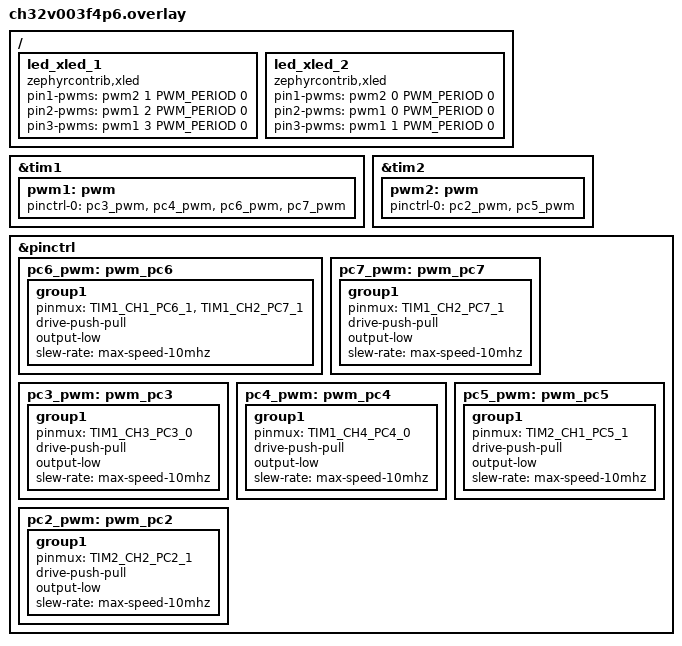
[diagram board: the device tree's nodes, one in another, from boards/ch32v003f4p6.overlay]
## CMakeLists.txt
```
cmake_minimum_required(VERSION 3.20.0)
list(APPEND ZEPHYR_EXTRA_MODULES ${CMAKE_CURRENT_LIST_DIR}/../..)
find_package(Zephyr REQUIRED HINTS $ENV{ZEPHYR_BASE})
project(xled_dual_sample)

target_sources(app PRIVATE src/main.c)
```

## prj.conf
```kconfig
CONFIG_PWM=y
CONFIG_GPIO=y
CONFIG_XLED=y

CONFIG_PRINTK=y
CONFIG_SERIAL=y
CONFIG_CONSOLE=y
CONFIG_UART_CONSOLE=y

CONFIG_CBPRINTF_NANO=y
CONFIG_CBPRINTF_REDUCED_INTEGRAL=y
CONFIG_TIMEOUT_64BIT=n

CONFIG_MINIMAL_LIBC=y
CONFIG_SYSTEM_WORKQUEUE_STACK_SIZE=160
CONFIG_MAIN_STACK_SIZE=320
CONFIG_IDLE_STACK_SIZE=64
CONFIG_ISR_STACK_SIZE=128

CONFIG_UART_INTERRUPT_DRIVEN=n
CONFIG_BOOT_BANNER=n
CONFIG_ASSERT=n
CONFIG_ERRNO=n
CONFIG_THREAD_NAME=n
```

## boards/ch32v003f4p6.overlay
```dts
#include <zephyr/dt-bindings/pinctrl/ch32v003-pinctrl.h>

#define PWM_PERIOD 20000

&tim1 {
	status = "okay";
	pwm1: pwm {
		status = "okay";
		pinctrl-0 = <&pc3_pwm &pc4_pwm &pc6_pwm &pc7_pwm>;
		pinctrl-names = "default";
	};
};

&tim2 {
	status = "okay";
	pwm2: pwm {
		status = "okay";
		pinctrl-0 = <&pc2_pwm &pc5_pwm>;
		pinctrl-names = "default";
	};
};

/ {
	led_xled_1: led_xled_1 {
		compatible = "zephyrcontrib,xled";
		pin1-pwms = <&pwm2 1 PWM_PERIOD 0>;
		pin2-pwms = <&pwm1 2 PWM_PERIOD 0>;
		pin3-pwms = <&pwm1 3 PWM_PERIOD 0>;
	};

	led_xled_2: led_xled_2 {
		compatible = "zephyrcontrib,xled";
		pin1-pwms = <&pwm2 0 PWM_PERIOD 0>;
		pin2-pwms = <&pwm1 0 PWM_PERIOD 0>;
		pin3-pwms = <&pwm1 1 PWM_PERIOD 0>;
	};
};

&pinctrl {
	pc6_pwm: pwm_pc6 {
		group1 {
			pinmux = <TIM1_CH1_PC6_1>, <TIM1_CH2_PC7_1>;
			drive-push-pull;
			output-low;
			slew-rate = "max-speed-10mhz";
		};
	};

	pc7_pwm: pwm_pc7 {
		group1 {
			pinmux = <TIM1_CH2_PC7_1>;
			drive-push-pull;
			output-low;
			slew-rate = "max-speed-10mhz";
		};
	};

	pc3_pwm: pwm_pc3 {
		group1 {
			pinmux = <TIM1_CH3_PC3_0>;
			drive-push-pull;
			output-low;
			slew-rate = "max-speed-10mhz";
		};
	};

	pc4_pwm: pwm_pc4 {
		group1 {
			pinmux = <TIM1_CH4_PC4_0>;
			drive-push-pull;
			output-low;
			slew-rate = "max-speed-10mhz";
		};
	};

	pc5_pwm: pwm_pc5 {
		group1 {
			pinmux = <TIM2_CH1_PC5_1>;
			drive-push-pull;
			output-low;
			slew-rate = "max-speed-10mhz";
		};
	};

	pc2_pwm: pwm_pc2 {
		group1 {
			pinmux = <TIM2_CH2_PC2_1>;
			drive-push-pull;
			output-low;
			slew-rate = "max-speed-10mhz";
		};
	};
};
```

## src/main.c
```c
/*
 * Copyright (c) 2026 Rohit
 *
 * SPDX-License-Identifier: Apache-2.0
 */

#include <zephyr/device.h>
#include <zephyr/devicetree.h>
#include <zephyr/drivers/xled.h>
#include <zephyr/kernel.h>

int main(void)
{
	const struct device *led1 = DEVICE_DT_GET(DT_NODELABEL(led_xled_1));
	const struct device *led2 = DEVICE_DT_GET(DT_NODELABEL(led_xled_2));

	if (!device_is_ready(led1) || !device_is_ready(led2)) {
		return 0;
	}

	while (1) {
		xled_set(led1, XLED_RGB_RED, 1000, 0);
		xled_set(led2, XLED_RGB_GREEN, 1000, 0);
		k_msleep(1000);

		xled_set(led1, XLED_RGB_WHITE, 1000, 250);
		xled_set(led2, XLED_RGB_BLUE, 1000, 0);
		k_msleep(2000);
	}
}
```
